# CW32L012 register map
Vendor: Wuhan Xinyuan Semiconductor Co.Ltd; Series: ARMCM0P; File version: 1.2
CPU: CM0+ r0p1, little endian, no MPU, no FPU, VTOR, 2 interrupt priority bits
Registers are 32-bit, read-write, no defined reset value unless marked. A register's access mark holds for its fields unless they carry their own. Offsets are from the block's base; [hi:lo] are bit positions.

## HALLTIM — HALL Timer
Base 0x40006400
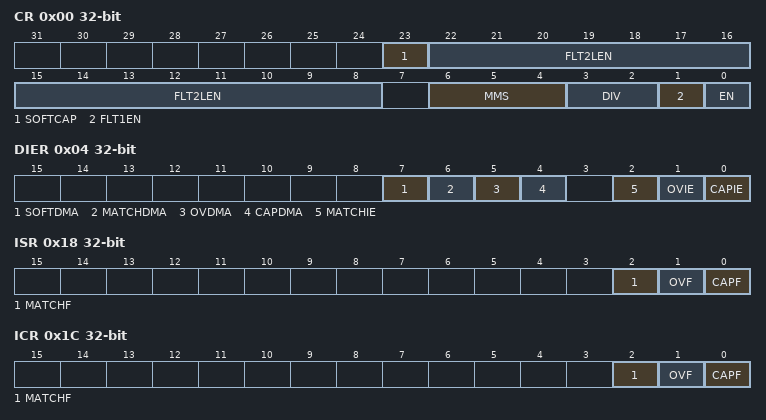
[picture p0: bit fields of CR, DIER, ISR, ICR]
0x00 CR — Control register1
  [23] SOFTCAP, [22:8] FLT2LEN, [6:4] MMS, [3:2] DIV, [1] FLT1EN, [0] EN
0x04 DIER — DMA and Interrupt register2
  [7] SOFTDMA, [6] MATCHDMA, [5] OVDMA, [4] CAPDMA, [2] MATCHIE, [1] OVIE, [0] CAPIE
0x08 CNT — counter register
  [23:0] DATA
0x0C ARR — Auto Reload Register
  [23:0] DATA
0x10 WIDTH ro
  [23:0] DATA
0x14 CCR — Compare control Register
  [23:0] DATA
0x18 ISR ro — Interrupt states register
  [2] MATCHF — desc MATCH
  [1] OVF — desc OV
  [0] CAPF
0x1C ICR — Interrupt clean register
  [2] MATCHF, [1] OVF, [0] CAPF
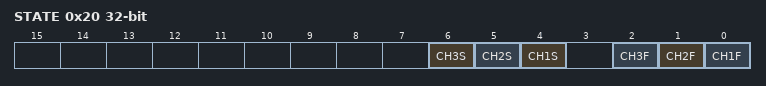
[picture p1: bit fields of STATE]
0x20 STATE ro
  [6] CH3S, [5] CH2S, [4] CH1S, [2] CH3F, [1] CH2F, [0] CH1F

## I2C1
Base 0x40005800
Same registers: I2C2 0x40005C00
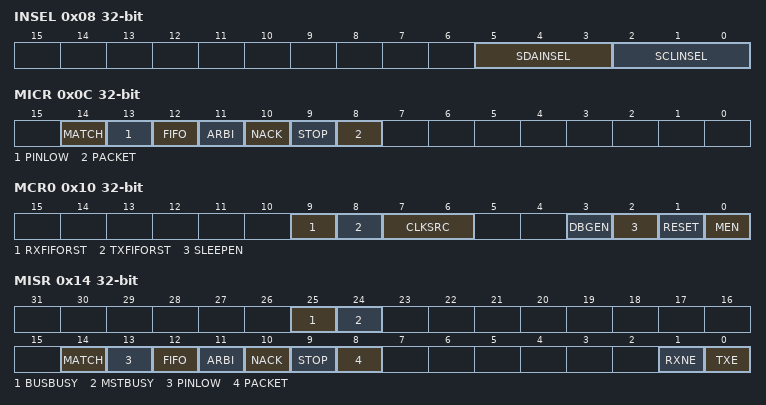
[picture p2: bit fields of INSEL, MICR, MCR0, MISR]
0x08 INSEL
  [5:3] SDAINSEL, [2:0] SCLINSEL
0x0C MICR — Master Interrupt Flag Clear Register
  [14] MATCH, [13] PINLOW, [12] FIFO, [11] ARBI, [10] NACK, [9] STOP, [8] PACKET
0x10 MCR0
  [9] RXFIFORST, [8] TXFIFORST, [7:6] CLKSRC, [3] DBGEN, [2] SLEEPEN, [1] RESET, [0] MEN
0x14 MISR ro — Master Interrupt Status Register
  [25] BUSBUSY, [24] MSTBUSY, [14] MATCH, [13] PINLOW, [12] FIFO, [11] ARBI, [10] NACK, [9] STOP, [8] PACKET, [1] RXNE, [0] TXE
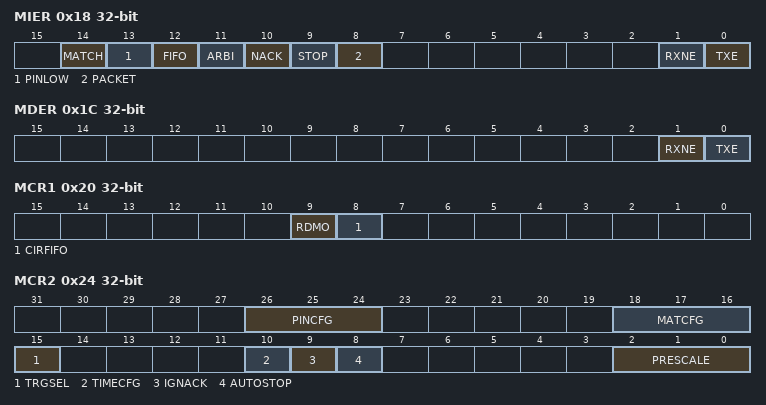
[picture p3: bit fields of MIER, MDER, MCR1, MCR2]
0x18 MIER — Master Interrupt Enable Register
  [14] MATCH, [13] PINLOW, [12] FIFO, [11] ARBI, [10] NACK, [9] STOP, [8] PACKET, [1] RXNE, [0] TXE
0x1C MDER — Master DMA Enable Register
  [1] RXNE, [0] TXE
0x20 MCR1 — Master Control Register1
  [9] RDMO, [8] CIRFIFO
0x24 MCR2 — Master Control Register2
  [26:24] PINCFG, [18:16] MATCFG, [15] TRGSEL, [10] TIMECFG, [9] IGNACK, [8] AUTOSTOP, [2:0] PRESCALE
0x24 SCR2 (alternate view of MCR2)
  [26:24] PINCFG
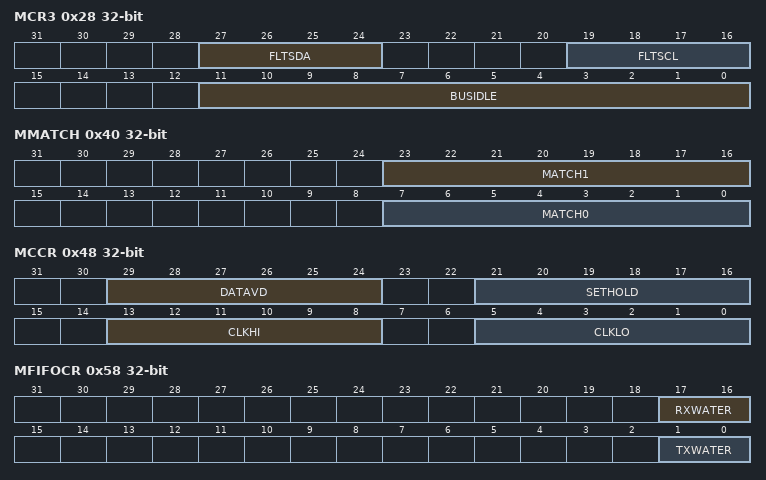
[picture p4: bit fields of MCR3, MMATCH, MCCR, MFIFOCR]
0x28 MCR3 — Master Control Register3
  [27:24] FLTSDA, [19:16] FLTSCL, [11:0] BUSIDLE
0x2C MCR4 — Master Control Register4
  [19:8] PINLOW
0x40 MMATCH — Master Match Register
  [23:16] MATCH1, [7:0] MATCH0
0x48 MCCR — Master Clock Control Register
  [29:24] DATAVD, [21:16] SETHOLD, [13:8] CLKHI, [5:0] CLKLO
0x58 MFIFOCR — Master FIFO Control Register
  [17:16] RXWATER, [1:0] TXWATER
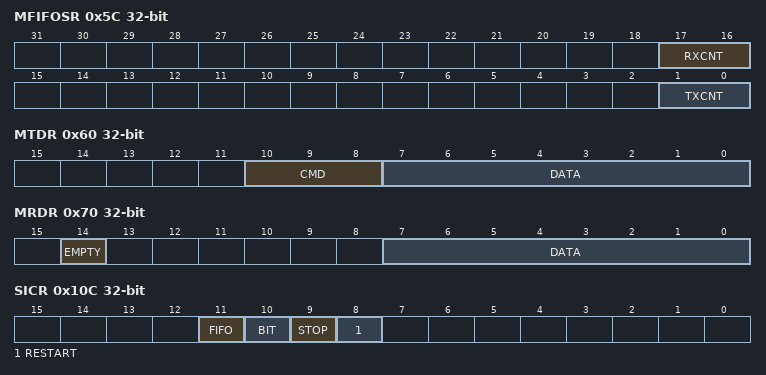
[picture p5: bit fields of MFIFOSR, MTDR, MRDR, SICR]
0x5C MFIFOSR ro — Master FIFO Status Register
  [17:16] RXCNT, [1:0] TXCNT
0x60 MTDR wo — Master Tx Data Register
  [10:8] CMD, [7:0] DATA
0x70 MRDR ro — Master Rx Data Register
  [14] EMPTY, [7:0] DATA
0x10C SICR
  [11] FIFO, [10] BIT, [9] STOP, [8] RESTART
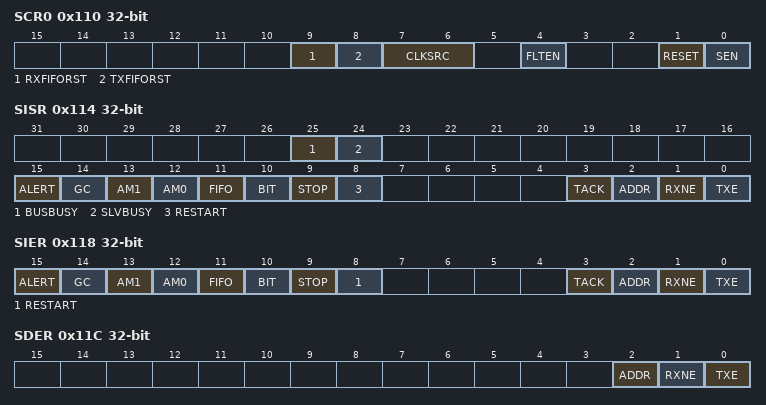
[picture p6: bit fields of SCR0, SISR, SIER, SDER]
0x110 SCR0 — Slave Control Register0
  [9] RXFIFORST, [8] TXFIFORST, [7:6] CLKSRC, [4] FLTEN, [1] RESET, [0] SEN
0x114 SISR ro
  [25] BUSBUSY, [24] SLVBUSY, [15] ALERT, [14] GC, [13] AM1, [12] AM0, [11] FIFO, [10] BIT, [9] STOP, [8] RESTART, [3] TACK, [2] ADDR, [1] RXNE, [0] TXE
0x118 SIER
  [15] ALERT, [14] GC, [13] AM1, [12] AM0, [11] FIFO, [10] BIT, [9] STOP, [8] RESTART, [3] TACK, [2] ADDR, [1] RXNE, [0] TXE
0x11C SDER
  [2] ADDR, [1] RXNE, [0] TXE
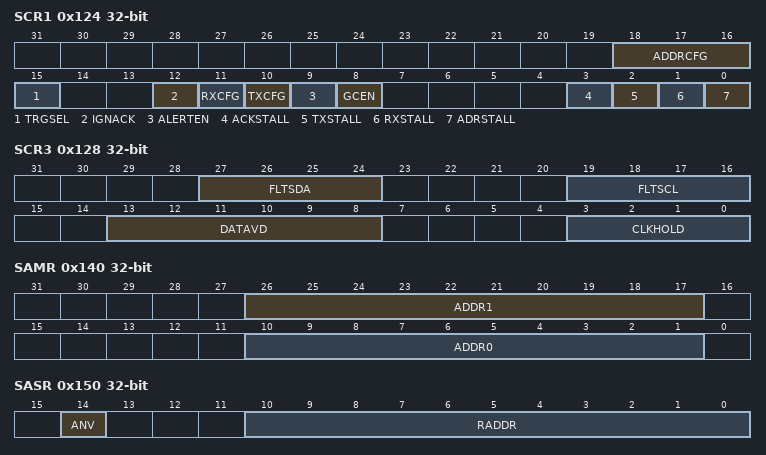
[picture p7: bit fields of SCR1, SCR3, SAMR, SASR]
0x124 SCR1
  [18:16] ADDRCFG, [15] TRGSEL, [12] IGNACK, [11] RXCFG, [10] TXCFG, [9] ALERTEN, [8] GCEN, [3] ACKSTALL, [2] TXSTALL, [1] RXSTALL, [0] ADRSTALL
0x128 SCR3
  [27:24] FLTSDA, [19:16] FLTSCL, [13:8] DATAVD, [3:0] CLKHOLD
0x140 SAMR
  [26:17] ADDR1, [10:1] ADDR0
0x150 SASR ro
  [14] ANV, [10:0] RADDR
0x154 STAR
  [0] TXNACK
0x160 STDR wo
  [7:0] DATA
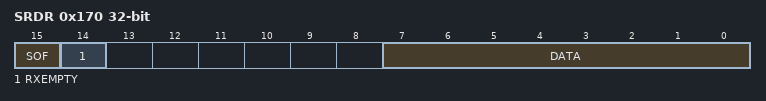
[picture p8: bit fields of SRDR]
0x170 SRDR ro
  [15] SOF, [14] RXEMPTY, [7:0] DATA

## IRMOD
Base 0x40004080
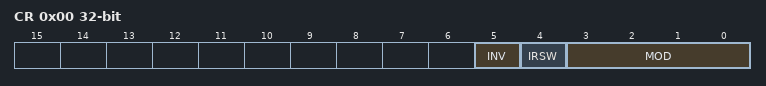
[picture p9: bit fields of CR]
0x00 CR — Input selection register
  [5] INV, [4] IRSW, [3:0] MOD

## IWDT
Base 0x40005000
0x00 KR wo — Key register
  [15:0] KR
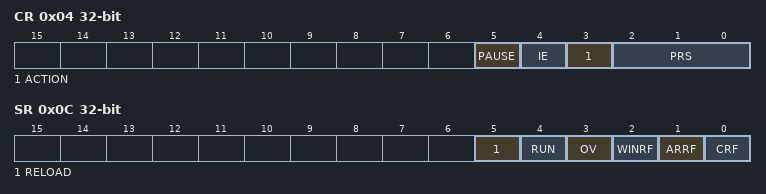
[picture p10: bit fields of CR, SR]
0x04 CR — Control register
  [5] PAUSE, [4] IE, [3] ACTION, [2:0] PRS
0x08 ARR — Auto reload register
  [11:0] ARR
0x0C SR — Status register
  [5] RELOAD ro, [4] RUN ro, [3] OV, [2] WINRF ro, [1] ARRF ro, [0] CRF ro
0x10 WINR — Window register
  [11:0] WINR
0x24 CNT ro — counter
  [11:0] CNT
